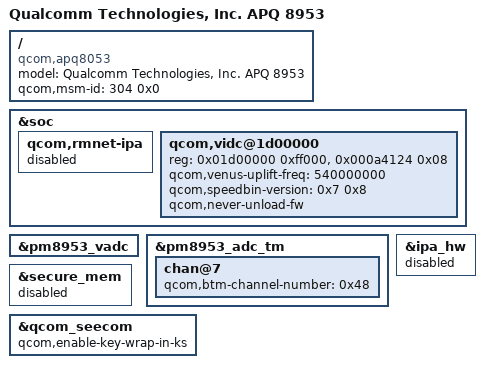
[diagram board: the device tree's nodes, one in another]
/*
 * Copyright (c) 2015-2018, The Linux Foundation. All rights reserved.
 *
 * This program is free software; you can redistribute it and/or modify
 * it under the terms of the GNU General Public License version 2 and
 * only version 2 as published by the Free Software Foundation.
 *
 * This program is distributed in the hope that it will be useful,
 * but WITHOUT ANY WARRANTY; without even the implied warranty of
 * MERCHANTABILITY or FITNESS FOR A PARTICULAR PURPOSE.  See the
 * GNU General Public License for more details.
 */

#include "msm8953.dtsi"
/ {
	model = "Qualcomm Technologies, Inc. APQ 8953";
	compatible = "qcom,apq8053";
	qcom,msm-id = <304 0x0>;
};

&soc {
	qcom,rmnet-ipa {
		status = "disabled";
	};
	qcom,vidc@1d00000 {
		reg = <0x01d00000 0xff000>,
			<0x000a4124 0x08>;
		reg-names = "vidc", "efuse";
		qcom,venus-uplift-freq = <540000000>;
		qcom,speedbin-version = <0x7 0x8>;
		qcom,never-unload-fw;
	};
};

&pm8953_vadc {
	/delete-node/ chan@36;
	/delete-node/ chan@11;
	/delete-node/ chan@13;
};

&pm8953_adc_tm {
	/delete-node/ chan@36;
	chan@7  {
		qcom,btm-channel-number = <0x48>;
	};
};

&ipa_hw {
	status = "disabled";
};

&secure_mem {
	status = "disabled";
};

&qcom_seecom {
	qcom,enable-key-wrap-in-ks;
};
